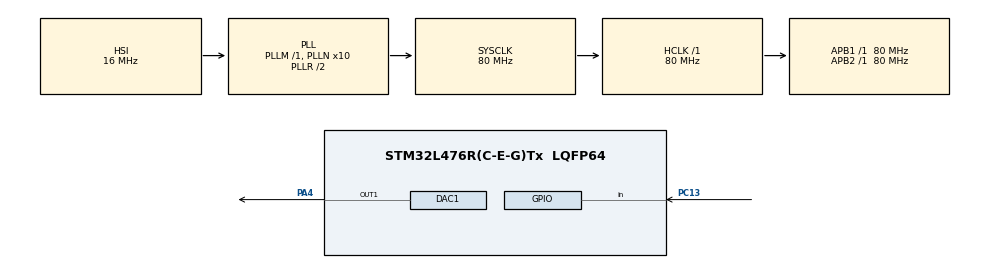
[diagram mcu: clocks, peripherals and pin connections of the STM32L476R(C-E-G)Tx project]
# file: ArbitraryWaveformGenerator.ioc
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DAC1.DAC_Trigger-DAC_OUT1=DAC_TRIGGER_T2_TRGO
Dma.DAC_CH1.0.Direction=DMA_MEMORY_TO_PERIPH
Dma.DAC_CH1.0.Instance=DMA1_Channel3
Dma.DAC_CH1.0.MemDataAlignment=DMA_MDATAALIGN_HALFWORD
Dma.DAC_CH1.0.MemInc=DMA_MINC_ENABLE
Dma.DAC_CH1.0.Mode=DMA_CIRCULAR
Dma.DAC_CH1.0.PeriphDataAlignment=DMA_PDATAALIGN_HALFWORD
Dma.DAC_CH1.0.PeriphInc=DMA_PINC_DISABLE
Dma.DAC_CH1.0.Priority=DMA_PRIORITY_LOW
Dma.Request0=DAC_CH1
Mcu.Family=STM32L4
Mcu.Name=STM32L476R(C-E-G)Tx
Mcu.Package=LQFP64
NVIC.DMA1_Channel3_IRQn=true\:0\:0\:false\:false\:true\:false\:true\:true
NVIC.PriorityGroup=NVIC_PRIORITYGROUP_4
PA4.Signal=COMP_DAC11_group
PC13.Signal=GPIO_Input
ProjectManager.HeapSize=0x200
ProjectManager.StackSize=0x400
ProjectManager.TargetToolchain=STM32CubeIDE
RCC.ADCFreq_Value=64000000
RCC.AHBFreq_Value=80000000
RCC.APB1Freq_Value=80000000
RCC.APB1TimFreq_Value=80000000
RCC.APB2Freq_Value=80000000
RCC.APB2TimFreq_Value=80000000
RCC.CortexFreq_Value=80000000
RCC.HCLKFreq_Value=80000000
RCC.HSE_VALUE=8000000
RCC.HSI_VALUE=16000000
RCC.LSE_VALUE=32768
RCC.MSI_VALUE=4000000
RCC.PLLN=10
RCC.PLLSourceVirtual=RCC_PLLSOURCE_HSI
RCC.PREFETCH_ENABLE=1
RCC.SYSCLKFreq_VALUE=80000000
RCC.SYSCLKSource=RCC_SYSCLKSOURCE_PLLCLK
RCC.USBFreq_Value=64000000
RCC.VCOOutputFreq_Value=160000000
SH.COMP_DAC11_group.0=DAC1_OUT1,DAC_OUT1
TIM2.AutoReloadPreload=TIM_AUTORELOAD_PRELOAD_ENABLE
TIM2.ClockDivision=TIM_CLOCKDIVISION_DIV1
TIM2.CounterMode=TIM_COUNTERMODE_DOWN
TIM2.Period=19
TIM2.Prescaler=3999
TIM2.TIM_MasterOutputTrigger=TIM_TRGO_UPDATE
VP_TIM2_VS_ClockSourceINT.Mode=Internal
board=NUCLEO-L476RG

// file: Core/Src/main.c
/* USER CODE BEGIN Header */
/**
  ******************************************************************************
  * @file           : main.c
  * @brief          : Main program body
  ******************************************************************************
  * @attention
  *
  * Copyright (c) 2025 STMicroelectronics.
  * All rights reserved.
  *
  * This software is licensed under terms that can be found in the LICENSE file
  * in the root directory of this software component.
  * If no LICENSE file comes with this software, it is provided AS-IS.
  *
  ******************************************************************************
  */
/* USER CODE END Header */
#include "main.h"

/* USER CODE BEGIN Includes */
#include "stdlib.h"
#include "math.h"
/* USER CODE END Includes */

/* USER CODE BEGIN PD */
#define Switch_Button GPIO_PIN_13

#define Samples 20
#define TOTAL_WAVEFORM 7

#define DAC_LOW_VALUE 1.3
#define LOW_PERIODS 20
/* USER CODE END PD */

DAC_HandleTypeDef hdac1;
DMA_HandleTypeDef hdma_dac_ch1;

TIM_HandleTypeDef htim2;

/* USER CODE BEGIN PV */

/*** DAC settings ***/
float DAC_RANGE = 4095;
uint32_t DACData = 0;
uint16_t DACValues_Sawtooth[Samples];
uint16_t DACValues_Square[Samples];
uint16_t DACValues_Sine[Samples];
uint16_t DACValues_Trapezoidal[Samples];
uint16_t DACValues_HalfSine[Samples];
uint16_t DACValues_Triangle[Samples];
uint16_t DACValues_Noise[Samples];
uint16_t* DACValues[TOTAL_WAVEFORM] = {
	DACValues_Sawtooth,
	DACValues_Square,
	DACValues_Sine,
    DACValues_Trapezoidal,
	DACValues_HalfSine,
	DACValues_Triangle,
	DACValues_Noise
};

/*** Clear waveform residuals ***/
uint16_t DACValues_Low[Samples];
uint8_t Is_DACValues_Low = 0;
uint8_t low_period_count = 0;
uint8_t Current_Waveform = 0;
uint8_t Want_Switch = 0;
uint8_t Next_Waveform = 0;

/*** Button state settings and debounce ***/
uint8_t button_state = 1;      // 0: pressed, 1: released
uint8_t last_button_state = 1; // 0: pressed, 1: released
uint8_t button_pressed = 0;    // 0: not handled, 1: already handled

/*** Waveform lookup table ***/
float Waveform_Sawtooth[Samples];
float Waveform_Square[Samples];
float Waveform_Sine[Samples];
float Waveform_Trapezoidal[Samples];
float Waveform_HalfSine[Samples];
float Waveform_Triangle[Samples];
float Waveform_Noise[Samples];

/* USER CODE END PV */

void SystemClock_Config(void);
static void MX_GPIO_Init(void);
static void MX_DMA_Init(void);
static void MX_DAC1_Init(void);
static void MX_TIM2_Init(void);

/* USER CODE BEGIN 0 */
void HAL_DAC_ConvCpltCallbackCh1(DAC_HandleTypeDef* hdac)
{
	if(Want_Switch)
	{
		Want_Switch = 0;
		low_period_count = 0;

		HAL_TIM_Base_Stop(&htim2);                     // Timer stop
		HAL_DAC_Stop_DMA(&hdac1, DAC_CHANNEL_1);       // DMA stop
		while((DMA1_Channel3->CCR & DMA_CCR_EN) != 0); // Wait for DMA stop

		HAL_DAC_Start_DMA(&hdac1, DAC_CHANNEL_1, (uint32_t*)DACValues_Low, Samples ,DAC_ALIGN_12B_R); // Clear waveform residuals
		HAL_TIM_Base_Start(&htim2); // Timer restart

		Is_DACValues_Low = 1;
	}
	else if(Is_DACValues_Low)
	{
		low_period_count++;

        if(low_period_count < LOW_PERIODS)
		{
        	HAL_TIM_Base_Stop(&htim2);                     // Timer stop
        	HAL_DAC_Stop_DMA(&hdac1, DAC_CHANNEL_1);       // DMA stop
        	while((DMA1_Channel3->CCR & DMA_CCR_EN) != 0); // Wait for DMA stop

        	HAL_DAC_Start_DMA(&hdac1, DAC_CHANNEL_1, (uint32_t*)DACValues_Low, Samples ,DAC_ALIGN_12B_R); // Clear waveform residuals
        	HAL_TIM_Base_Start(&htim2); // Timer restart
		}
		else
		{
			Is_DACValues_Low = 0;

			HAL_TIM_Base_Stop(&htim2);                     // Timer stop
        	HAL_DAC_Stop_DMA(&hdac1, DAC_CHANNEL_1);       // DMA stop
	        while((DMA1_Channel3->CCR & DMA_CCR_EN) != 0); // Wait for DMA stop

	    	HAL_DAC_Start_DMA(&hdac1, DAC_CHANNEL_1, (uint32_t*)DACValues[Next_Waveform], Samples ,DAC_ALIGN_12B_R); // Switch to next waveform
	        HAL_TIM_Base_Start(&htim2); // Timer restart
		}
	}
}

void Generate_Waveforms(void)
{
	/*** Waveforms: Min voltage: 1.3V, Max voltage: 2.0V ***/

	// Sawtooth
	for(int i = 0; i < Samples; i++)
	{
		Waveform_Sawtooth[i] = 1.3 + 0.7 * i / (Samples - 1);
		DACValues_Sawtooth[i] = (uint16_t)(Waveform_Sawtooth[i] * DAC_RANGE / 3.3);
	}

	// Squarewave
	for(int i = 0; i < Samples; i++)
	{
		if(i < (Samples / 2))
			Waveform_Square[i] = 1.3;
		else
			Waveform_Square[i] = 2.0;
		DACValues_Square[i] = (uint16_t)(Waveform_Square[i] * DAC_RANGE / 3.3);
	}

	// Sinewave
	for(int i = 0; i < Samples; i++)
	{
		Waveform_Sine[i] = 1.65 + 0.35 * sin(2.0 * 3.141592 * i / Samples);
		DACValues_Sine[i] = (uint16_t)(Waveform_Sine[i] * DAC_RANGE / 3.3);
	}

	// Trapezoidal
	int rise = Samples * 0.2;
	int high = Samples * 0.5;
	int fall = Samples * 0.7;
	for(int i = 0; i < Samples; i++)
	{
		if(i < rise)
			Waveform_Trapezoidal[i] = 1.3 + 0.7 * i / rise;
		else if(i < high)
			Waveform_Trapezoidal[i] = 2.0;
		else if(i < fall)
			Waveform_Trapezoidal[i] = 2.0 - 0.7 * (i - high) / (fall - high);
		else
			Waveform_Trapezoidal[i] = 1.3;
		DACValues_Trapezoidal[i] = (uint16_t)(Waveform_Trapezoidal[i] * DAC_RANGE / 3.3);
	}

	// HalfSine
	for(int i = 0; i < Samples; i++)
	{
		Waveform_HalfSine[i] = 1.3 + 0.7 * sin(3.141592 * i / Samples);
		DACValues_HalfSine[i] = (uint16_t)(Waveform_HalfSine[i] * DAC_RANGE / 3.3);
	}

	// Triangle
	for(int i = 0; i < Samples; i++)
	{
		if(i < (Samples / 2))
			Waveform_Triangle[i] = 1.3 + 0.7 * (2.0 * i) / Samples;
		else
			Waveform_Triangle[i] = 2.0 - 0.7 * (2.0 * (i - Samples / 2)) / Samples;
		DACValues_Triangle[i] = (uint16_t)(Waveform_Triangle[i] * DAC_RANGE / 3.3);
	}

	// Noise
	for(int i = 0; i < Samples; i++)
	{
		float rand_value = (float)rand() / RAND_MAX;
		Waveform_Noise[i] = 1.3 + 0.7 * rand_value;
		DACValues_Noise[i] = (uint16_t)(Waveform_Noise[i] * DAC_RANGE / 3.3);
	}
}

void Generate_Low_Wave(void)
{
	for(int i = 0; i < Samples; i++)
		DACValues_Low[i] = (uint16_t)(DAC_LOW_VALUE * DAC_RANGE / 3.3);
}
/* USER CODE END 0 */

int main(void)
{

  /* MCU Configuration--------------------------------------------------------*/

  /* Reset of all peripherals, Initializes the Flash interface and the Systick. */
  HAL_Init();

  /* USER CODE BEGIN Init */
  Generate_Waveforms();
  Generate_Low_Wave(); // Low Wave for clear waveform residuals
  /* USER CODE END Init */

  /* Configure the system clock */
  SystemClock_Config();

  /* Initialize all configured peripherals */
  MX_GPIO_Init();
  MX_DMA_Init();
  MX_DAC1_Init();
  MX_TIM2_Init();
  /* USER CODE BEGIN 2 */
  HAL_DAC_Init(&hdac1);
  HAL_DAC_Start_DMA(&hdac1, DAC_CHANNEL_1, (uint32_t*)DACValues[Current_Waveform], Samples ,DAC_ALIGN_12B_R);
  HAL_TIM_Base_Start(&htim2);
  /* USER CODE END 2 */

  /* Infinite loop */
  /* USER CODE BEGIN WHILE */
  while (1)
  {
	  button_state = HAL_GPIO_ReadPin(GPIOC, Switch_Button); // Read button state

	  if(button_state == 0 && last_button_state == 1 && button_pressed == 0)
	  {
		  HAL_Delay(50); // Debounce delay
		  if(HAL_GPIO_ReadPin(GPIOC, Switch_Button) == 0)
		  {
			  Next_Waveform = (Current_Waveform + 1) % TOTAL_WAVEFORM; // Set next waveform
			  Current_Waveform = Next_Waveform;
			  Want_Switch = 1;
			  button_pressed = 1;
		  }
	  }
	  if(button_state == 1) // Allow next press
	  {
		  button_pressed = 0;
	  }

	  last_button_state = button_state;
    /* USER CODE END WHILE */

  }
}

void SystemClock_Config(void)
{
  RCC_OscInitTypeDef RCC_OscInitStruct = {0};
  RCC_ClkInitTypeDef RCC_ClkInitStruct = {0};

  /** Configure the main internal regulator output voltage
  */
  if (HAL_PWREx_ControlVoltageScaling(PWR_REGULATOR_VOLTAGE_SCALE1) != HAL_OK)
  {
    Error_Handler();
  }

  /** Initializes the RCC Oscillators according to the specified parameters
  * in the RCC_OscInitTypeDef structure.
  */
  RCC_OscInitStruct.OscillatorType = RCC_OSCILLATORTYPE_HSI;
  RCC_OscInitStruct.HSIState = RCC_HSI_ON;
  RCC_OscInitStruct.HSICalibrationValue = RCC_HSICALIBRATION_DEFAULT;
  RCC_OscInitStruct.PLL.PLLState = RCC_PLL_ON;
  RCC_OscInitStruct.PLL.PLLSource = RCC_PLLSOURCE_HSI;
  RCC_OscInitStruct.PLL.PLLM = 1;
  RCC_OscInitStruct.PLL.PLLN = 10;
  RCC_OscInitStruct.PLL.PLLP = RCC_PLLP_DIV7;
  RCC_OscInitStruct.PLL.PLLQ = RCC_PLLQ_DIV2;
  RCC_OscInitStruct.PLL.PLLR = RCC_PLLR_DIV2;
  if (HAL_RCC_OscConfig(&RCC_OscInitStruct) != HAL_OK)
  {
    Error_Handler();
  }

  /** Initializes the CPU, AHB and APB buses clocks
  */
  RCC_ClkInitStruct.ClockType = RCC_CLOCKTYPE_HCLK|RCC_CLOCKTYPE_SYSCLK
                              |RCC_CLOCKTYPE_PCLK1|RCC_CLOCKTYPE_PCLK2;
  RCC_ClkInitStruct.SYSCLKSource = RCC_SYSCLKSOURCE_PLLCLK;
  RCC_ClkInitStruct.AHBCLKDivider = RCC_SYSCLK_DIV1;
  RCC_ClkInitStruct.APB1CLKDivider = RCC_HCLK_DIV1;
  RCC_ClkInitStruct.APB2CLKDivider = RCC_HCLK_DIV1;

  if (HAL_RCC_ClockConfig(&RCC_ClkInitStruct, FLASH_LATENCY_4) != HAL_OK)
  {
    Error_Handler();
  }
}

static void MX_DAC1_Init(void)
{

  DAC_ChannelConfTypeDef sConfig = {0};

  /** DAC Initialization
  */
  hdac1.Instance = DAC1;
  if (HAL_DAC_Init(&hdac1) != HAL_OK)
  {
    Error_Handler();
  }

  /** DAC channel OUT1 config
  */
  sConfig.DAC_SampleAndHold = DAC_SAMPLEANDHOLD_DISABLE;
  sConfig.DAC_Trigger = DAC_TRIGGER_T2_TRGO;
  sConfig.DAC_OutputBuffer = DAC_OUTPUTBUFFER_ENABLE;
  sConfig.DAC_ConnectOnChipPeripheral = DAC_CHIPCONNECT_DISABLE;
  sConfig.DAC_UserTrimming = DAC_TRIMMING_FACTORY;
  if (HAL_DAC_ConfigChannel(&hdac1, &sConfig, DAC_CHANNEL_1) != HAL_OK)
  {
    Error_Handler();
  }

}

static void MX_TIM2_Init(void)
{

  TIM_ClockConfigTypeDef sClockSourceConfig = {0};
  TIM_MasterConfigTypeDef sMasterConfig = {0};

  htim2.Instance = TIM2;
  htim2.Init.Prescaler = 3999;
  htim2.Init.CounterMode = TIM_COUNTERMODE_DOWN;
  htim2.Init.Period = 19;
  htim2.Init.ClockDivision = TIM_CLOCKDIVISION_DIV1;
  htim2.Init.AutoReloadPreload = TIM_AUTORELOAD_PRELOAD_ENABLE;
  if (HAL_TIM_Base_Init(&htim2) != HAL_OK)
  {
    Error_Handler();
  }
  sClockSourceConfig.ClockSource = TIM_CLOCKSOURCE_INTERNAL;
  if (HAL_TIM_ConfigClockSource(&htim2, &sClockSourceConfig) != HAL_OK)
  {
    Error_Handler();
  }
  sMasterConfig.MasterOutputTrigger = TIM_TRGO_UPDATE;
  sMasterConfig.MasterSlaveMode = TIM_MASTERSLAVEMODE_DISABLE;
  if (HAL_TIMEx_MasterConfigSynchronization(&htim2, &sMasterConfig) != HAL_OK)
  {
    Error_Handler();
  }

}

static void MX_DMA_Init(void)
{

  /* DMA controller clock enable */
  __HAL_RCC_DMA1_CLK_ENABLE();

  /* DMA interrupt init */
  /* DMA1_Channel3_IRQn interrupt configuration */
  HAL_NVIC_SetPriority(DMA1_Channel3_IRQn, 0, 0);
  HAL_NVIC_EnableIRQ(DMA1_Channel3_IRQn);

}

static void MX_GPIO_Init(void)
{
  GPIO_InitTypeDef GPIO_InitStruct = {0};

  /* GPIO Ports Clock Enable */
  __HAL_RCC_GPIOC_CLK_ENABLE();
  __HAL_RCC_GPIOA_CLK_ENABLE();

  /*Configure GPIO pin : PC13 */
  GPIO_InitStruct.Pin = GPIO_PIN_13;
  GPIO_InitStruct.Mode = GPIO_MODE_INPUT;
  GPIO_InitStruct.Pull = GPIO_NOPULL;
  HAL_GPIO_Init(GPIOC, &GPIO_InitStruct);

}

void Error_Handler(void)
{
  __disable_irq();
  while (1)
  {
  }
}
